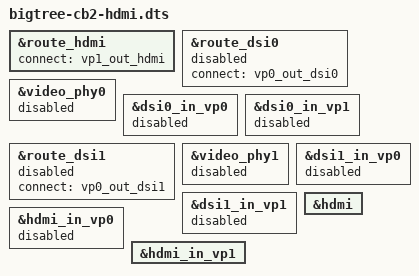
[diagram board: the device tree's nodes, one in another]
/dts-v1/;
/plugin/;

/ {
	
	fragment@0 {
		target = <&route_hdmi>;

		__overlay__ {
			status = "okay";
			connect = <&vp1_out_hdmi>;
		};
	};

	fragment@1 {
		target = <&route_dsi0>;

		__overlay__ {
			status = "disabled";
			connect = <&vp0_out_dsi0>;
		};
	};

	fragment@2 {
		target = <&video_phy0>;

		__overlay__ {
			status = "disabled";
		};
	};

	fragment@3 {
		target = <&dsi0_in_vp0>;

		__overlay__ {
			status = "disabled";
		};
	};
	
	fragment@4 {
		target = <&dsi0_in_vp1>;

		__overlay__ {
			status = "disabled";
		};
	};

	fragment@5 {
		target = <&route_dsi1>;

		__overlay__ {
			status = "disabled";
			connect = <&vp0_out_dsi1>;
		};
	};

	fragment@6 {
		target = <&video_phy1>;

		__overlay__ {
			status = "disabled";
		};
	};

	fragment@7 {
		target = <&dsi1_in_vp0>;

		__overlay__ {
			status = "disabled";
		};
	};
	
	fragment@8 {
		target = <&dsi1_in_vp1>;

		__overlay__ {
			status = "disabled";
		};
	};

	fragment@9 {
		target = <&hdmi>;

		__overlay__ {
			status = "okay";
		};
	};

	fragment@10 {
		target = <&hdmi_in_vp0>;

		__overlay__ {
			status = "disabled";
		};
	};

	fragment@11 {
		target = <&hdmi_in_vp1>;

		__overlay__ {
			status = "okay";
		};
	};
};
